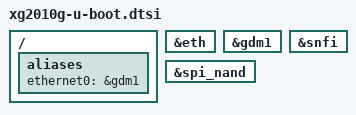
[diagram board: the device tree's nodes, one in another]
// SPDX-License-Identifier: GPL-2.0+

/*
 * U-Boot-specific hardware description.  The SoC description and the
 * board-level memory layout live in xg2010g.dts.
 */

#include "an7581-u-boot.dtsi"

/* The board reserves the complete first 2 MiB for the early boot chain. */
/delete-node/ &atf_reserved;

/ {
	aliases {
		ethernet0 = &gdm1;
	};
};

/* Enable the FE/QDMA block for the single recovery path. */
&eth {
	status = "okay";
};

/* gdm1 is the internal switch CPU port used by Web Recovery. */
&gdm1 {
	status = "okay";
};

&snfi {
	status = "okay";
};

&spi_nand {
	status = "okay";
};
